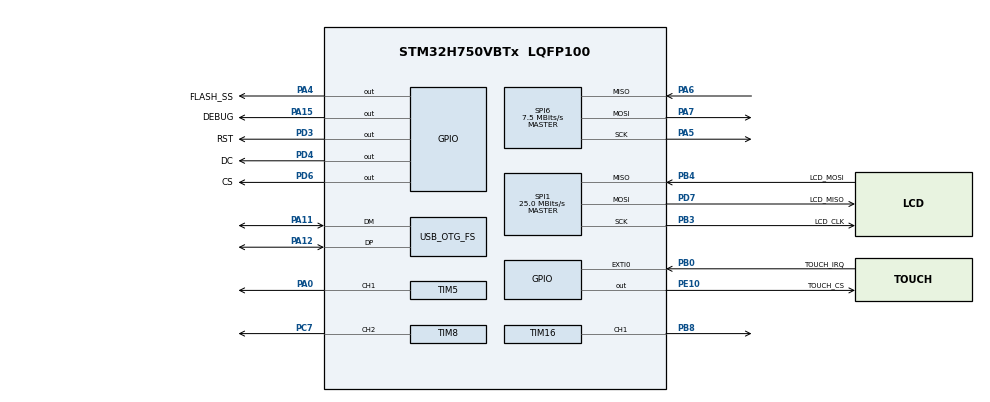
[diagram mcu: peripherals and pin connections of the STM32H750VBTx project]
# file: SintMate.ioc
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CORTEX_M7.CPU_DCache=Disabled
CORTEX_M7.CPU_ICache=Enabled
Dma.Request0=SPI1_TX
Dma.Request1=TIM8_CH2
Dma.SPI1_TX.0.Direction=DMA_MEMORY_TO_PERIPH
Dma.SPI1_TX.0.EventEnable=DISABLE
Dma.SPI1_TX.0.FIFOMode=DMA_FIFOMODE_DISABLE
Dma.SPI1_TX.0.Instance=DMA1_Stream0
Dma.SPI1_TX.0.MemDataAlignment=DMA_MDATAALIGN_BYTE
Dma.SPI1_TX.0.MemInc=DMA_MINC_ENABLE
Dma.SPI1_TX.0.Mode=DMA_NORMAL
Dma.SPI1_TX.0.PeriphDataAlignment=DMA_PDATAALIGN_BYTE
Dma.SPI1_TX.0.PeriphInc=DMA_PINC_DISABLE
Dma.SPI1_TX.0.Polarity=HAL_DMAMUX_REQ_GEN_RISING
Dma.SPI1_TX.0.Priority=DMA_PRIORITY_LOW
Dma.SPI1_TX.0.RequestNumber=1
Dma.SPI1_TX.0.SignalID=NONE
Dma.SPI1_TX.0.SyncEnable=DISABLE
Dma.SPI1_TX.0.SyncPolarity=HAL_DMAMUX_SYNC_NO_EVENT
Dma.SPI1_TX.0.SyncRequestNumber=1
Dma.SPI1_TX.0.SyncSignalID=NONE
Dma.TIM8_CH2.1.Direction=DMA_MEMORY_TO_PERIPH
Dma.TIM8_CH2.1.EventEnable=DISABLE
Dma.TIM8_CH2.1.FIFOMode=DMA_FIFOMODE_DISABLE
Dma.TIM8_CH2.1.Instance=DMA1_Stream1
Dma.TIM8_CH2.1.MemDataAlignment=DMA_MDATAALIGN_WORD
Dma.TIM8_CH2.1.MemInc=DMA_MINC_ENABLE
Dma.TIM8_CH2.1.Mode=DMA_CIRCULAR
Dma.TIM8_CH2.1.PeriphDataAlignment=DMA_PDATAALIGN_WORD
Dma.TIM8_CH2.1.PeriphInc=DMA_PINC_DISABLE
Dma.TIM8_CH2.1.Polarity=HAL_DMAMUX_REQ_GEN_RISING
Dma.TIM8_CH2.1.Priority=DMA_PRIORITY_LOW
Dma.TIM8_CH2.1.RequestNumber=1
Dma.TIM8_CH2.1.SignalID=NONE
Dma.TIM8_CH2.1.SyncEnable=DISABLE
Dma.TIM8_CH2.1.SyncPolarity=HAL_DMAMUX_SYNC_NO_EVENT
Dma.TIM8_CH2.1.SyncRequestNumber=1
Dma.TIM8_CH2.1.SyncSignalID=NONE
Mcu.Family=STM32H7
Mcu.Name=STM32H750VBTx
Mcu.Package=LQFP100
NVIC.DMA1_Stream0_IRQn=true\:0\:0\:false\:false\:true\:false\:true
NVIC.DMA1_Stream1_IRQn=true\:0\:0\:false\:false\:true\:false\:true
NVIC.EXTI0_IRQn=true\:0\:0\:false\:false\:true\:true\:true
NVIC.OTG_FS_IRQn=true\:0\:0\:false\:false\:true\:false\:true
NVIC.PriorityGroup=NVIC_PRIORITYGROUP_4
NVIC.SPI1_IRQn=true\:0\:0\:false\:false\:true\:false\:true
NVIC.TIM7_IRQn=true\:0\:0\:false\:false\:true\:true\:true
PA0.Signal=S_TIM5_CH1
PA11.Mode=Device_Only
PA11.Signal=USB_OTG_FS_DM
PA12.Mode=Device_Only
PA12.Signal=USB_OTG_FS_DP
PA15\ (JTDI).GPIO_Label=DEBUG
PA15\ (JTDI).Signal=GPIO_Output
PA4.GPIO_Label=FLASH_SS
PA4.Signal=GPIO_Output
PA5.Mode=Full_Duplex_Master
PA5.Signal=SPI6_SCK
PA6.Mode=Full_Duplex_Master
PA6.Signal=SPI6_MISO
PA7.Mode=Full_Duplex_Master
PA7.Signal=SPI6_MOSI
PB0.GPIO_Label=TOUCH_IRQ
PB0.GPIO_ModeDefaultEXTI=GPIO_MODE_IT_RISING_FALLING
PB0.GPIO_PuPd=GPIO_PULLUP
PB0.Signal=GPXTI0
PB3\ (JTDO/TRACESWO).GPIO_Label=LCD_CLK
PB3\ (JTDO/TRACESWO).Mode=Full_Duplex_Master
PB3\ (JTDO/TRACESWO).Signal=SPI1_SCK
PB4\ (NJTRST).GPIO_Label=LCD_MOSI
PB4\ (NJTRST).Mode=Full_Duplex_Master
PB4\ (NJTRST).Signal=SPI1_MISO
PB8.Signal=S_TIM16_CH1
PC7.Signal=S_TIM8_CH2
PD3.GPIO_Label=RST
PD3.Signal=GPIO_Output
PD4.GPIO_Label=DC
PD4.GPIO_Speed=GPIO_SPEED_FREQ_HIGH
PD4.Signal=GPIO_Output
PD6.GPIO_Label=CS
PD6.GPIO_Speed=GPIO_SPEED_FREQ_HIGH
PD6.PinState=GPIO_PIN_SET
PD6.Signal=GPIO_Output
PD7.GPIO_Label=LCD_MISO
PD7.Mode=Full_Duplex_Master
PD7.Signal=SPI1_MOSI
PE10.GPIO_Label=TOUCH_CS
PE10.GPIO_Speed=GPIO_SPEED_FREQ_HIGH
PE10.PinState=GPIO_PIN_SET
PE10.Signal=GPIO_Output
PH0-OSC_IN\ (PH0).Mode=HSE-External-Oscillator
PH0-OSC_IN\ (PH0).Signal=RCC_OSC_IN
PH1-OSC_OUT\ (PH1).Mode=HSE-External-Oscillator
PH1-OSC_OUT\ (PH1).Signal=RCC_OSC_OUT
ProjectManager.HeapSize=0x200
ProjectManager.StackSize=0x400
ProjectManager.TargetToolchain=STM32CubeIDE
RCC.ADCFreq_Value=200000000
RCC.APB1Freq_Value=120000000
RCC.APB2Freq_Value=120000000
RCC.APB3Freq_Value=120000000
RCC.APB4Freq_Value=120000000
RCC.CortexFreq_Value=480000000
RCC.D1PPRE=RCC_APB3_DIV2
RCC.D2PPRE1=RCC_APB1_DIV2
RCC.D2PPRE2=RCC_APB2_DIV2
RCC.D3PPRE=RCC_APB4_DIV2
RCC.DIVM1=2
RCC.DIVM2=12
RCC.DIVM3=16
RCC.DIVN1=80
RCC.DIVN2=200
RCC.DIVN3=144
RCC.DIVP3=1
RCC.HCLKFreq_Value=240000000
RCC.HPRE=RCC_HCLK_DIV2
RCC.HSE_VALUE=24000000
RCC.PLLFRACN=0
RCC.PLLSourceVirtual=RCC_PLLSOURCE_HSE
RCC.SPI123CLockSelection=RCC_SPI123CLKSOURCE_PLL2
RCC.SYSCLKFreq_VALUE=480000000
RCC.SYSCLKSource=RCC_SYSCLKSOURCE_PLLCLK
RCC.USBCLockSelection=RCC_USBCLKSOURCE_HSI48
RCC.USBFreq_Value=48000000
RCC.VDD_VALUE=3
SH.S_TIM16_CH1.0=TIM16_CH1,Output Compare1 CH1
SH.S_TIM5_CH1.0=TIM5_CH1,PWM Generation1 CH1
SH.S_TIM8_CH2.0=TIM8_CH2,PWM Generation2 CH2
SPI1.BaudRatePrescaler=SPI_BAUDRATEPRESCALER_8
SPI1.CalculateBaudRate=25.0 MBits/s
SPI1.DataSize=SPI_DATASIZE_8BIT
SPI1.Direction=SPI_DIRECTION_2LINES
SPI1.Mode=SPI_MODE_MASTER
SPI1.VirtualType=VM_MASTER
SPI6.BaudRatePrescaler=SPI_BAUDRATEPRESCALER_16
SPI6.CalculateBaudRate=7.5 MBits/s
SPI6.DataSize=SPI_DATASIZE_8BIT
SPI6.Direction=SPI_DIRECTION_2LINES
SPI6.Mode=SPI_MODE_MASTER
SPI6.VirtualType=VM_MASTER
TIM16.Channel=TIM_CHANNEL_1
TIM16.OCMode_1=TIM_OCMODE_TOGGLE
TIM16.Period=50
TIM16.Prescaler=8571
TIM16.Pulse=25
TIM16.RepetitionCounter=7
TIM5.Channel-PWM\ Generation1\ CH1=TIM_CHANNEL_1
TIM5.Period=1000
TIM5.Prescaler=240
TIM5.Pulse-PWM\ Generation1\ CH1=500
TIM7.Period=10000
TIM7.Prescaler=2400
TIM8.Channel-PWM\ Generation2\ CH2=TIM_CHANNEL_2
TIM8.Period=1200
TIM8.Prescaler=3
TIM8.Pulse-PWM\ Generation2\ CH2=400
USB_DEVICE.CLASS_NAME_FS=CDC
USB_DEVICE.VirtualMode-CDC_FS=Cdc
USB_DEVICE.VirtualModeFS=Cdc_FS
USB_OTG_FS.VirtualMode=Device_Only
VP_TIM16_VS_ClockSourceINT.Mode=Enable_Timer
VP_TIM16_VS_OPM.Mode=OPM_bit
VP_TIM7_VS_ClockSourceINT.Mode=Enable_Timer
VP_USB_DEVICE_VS_USB_DEVICE_CDC_FS.Mode=CDC_FS
board=custom

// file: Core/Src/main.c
/* USER CODE BEGIN Header */
/**
  ******************************************************************************
  * @file           : main.c
  * @brief          : Main program body
  ******************************************************************************
  * @attention
  *
  * <h2><center>&copy; Copyright (c) 2021 STMicroelectronics.
  * All rights reserved.</center></h2>
  *
  * This software component is licensed by ST under BSD 3-Clause license,
  * the "License"; You may not use this file except in compliance with the
  * License. You may obtain a copy of the License at:
  *                        opensource.org/licenses/BSD-3-Clause
  *
  ******************************************************************************
  */
/* USER CODE END Header */
#include "main.h"
#include "usb_device.h"

/* USER CODE BEGIN Includes */
#include <stdio.h>
#include <string.h>

/* USER CODE END Includes */

SPI_HandleTypeDef hspi1;
SPI_HandleTypeDef hspi6;
DMA_HandleTypeDef hdma_spi1_tx;

TIM_HandleTypeDef htim5;
TIM_HandleTypeDef htim7;
TIM_HandleTypeDef htim8;
TIM_HandleTypeDef htim16;
DMA_HandleTypeDef hdma_tim8_ch2;

void SystemClock_Config(void);
static void MX_GPIO_Init(void);
static void MX_DMA_Init(void);
static void MX_SPI1_Init(void);
static void MX_SPI6_Init(void);
static void MX_TIM5_Init(void);
static void MX_TIM7_Init(void);
static void MX_TIM16_Init(void);
static void MX_TIM8_Init(void);

int main(void)
{

  /* Enable I-Cache---------------------------------------------------------*/
  SCB_EnableICache();

  /* MCU Configuration--------------------------------------------------------*/

  /* Reset of all peripherals, Initializes the Flash interface and the Systick. */
  HAL_Init();

  /* Configure the system clock */
  SystemClock_Config();

  /* USER CODE BEGIN SysInit */
  __HAL_RCC_D2SRAM1_CLK_ENABLE();
  __HAL_RCC_D2SRAM2_CLK_ENABLE();
  __HAL_RCC_D2SRAM3_CLK_ENABLE();

  /* USER CODE END SysInit */

  /* Initialize all configured peripherals */
  MX_GPIO_Init();
  MX_DMA_Init();
  MX_SPI1_Init();
  MX_SPI6_Init();
  MX_TIM5_Init();
  MX_TIM7_Init();
  MX_TIM16_Init();
  MX_TIM8_Init();
  MX_USB_DEVICE_Init();
  /* USER CODE BEGIN 2 */
  Init_SintMate();
  /* USER CODE END 2 */

  /* Infinite loop */
  /* USER CODE BEGIN WHILE */
  while (1)
  {
	  SintMateLoop();

	  //DoNumberOfSteps(4);
	  /*
		HAL_TIM_OC_Start(&htim16, TIM_CHANNEL_1);
		HAL_Delay(100);
		//HAL_TIM_OC_Stop(&htim16, TIM_CHANNEL_1);
		 *
		 */

    /* USER CODE END WHILE */

  }
}

void SystemClock_Config(void)
{
  RCC_OscInitTypeDef RCC_OscInitStruct = {0};
  RCC_ClkInitTypeDef RCC_ClkInitStruct = {0};
  RCC_PeriphCLKInitTypeDef PeriphClkInitStruct = {0};

  /** Supply configuration update enable
  */
  HAL_PWREx_ConfigSupply(PWR_LDO_SUPPLY);
  /** Configure the main internal regulator output voltage
  */
  __HAL_PWR_VOLTAGESCALING_CONFIG(PWR_REGULATOR_VOLTAGE_SCALE0);

  while(!__HAL_PWR_GET_FLAG(PWR_FLAG_VOSRDY)) {}
  /** Macro to configure the PLL clock source
  */
  __HAL_RCC_PLL_PLLSOURCE_CONFIG(RCC_PLLSOURCE_HSE);
  /** Initializes the RCC Oscillators according to the specified parameters
  * in the RCC_OscInitTypeDef structure.
  */
  RCC_OscInitStruct.OscillatorType = RCC_OSCILLATORTYPE_HSI48|RCC_OSCILLATORTYPE_HSE;
  RCC_OscInitStruct.HSEState = RCC_HSE_ON;
  RCC_OscInitStruct.HSI48State = RCC_HSI48_ON;
  RCC_OscInitStruct.PLL.PLLState = RCC_PLL_ON;
  RCC_OscInitStruct.PLL.PLLSource = RCC_PLLSOURCE_HSE;
  RCC_OscInitStruct.PLL.PLLM = 2;
  RCC_OscInitStruct.PLL.PLLN = 80;
  RCC_OscInitStruct.PLL.PLLP = 2;
  RCC_OscInitStruct.PLL.PLLQ = 2;
  RCC_OscInitStruct.PLL.PLLR = 2;
  RCC_OscInitStruct.PLL.PLLRGE = RCC_PLL1VCIRANGE_3;
  RCC_OscInitStruct.PLL.PLLVCOSEL = RCC_PLL1VCOWIDE;
  RCC_OscInitStruct.PLL.PLLFRACN = 0;
  if (HAL_RCC_OscConfig(&RCC_OscInitStruct) != HAL_OK)
  {
    Error_Handler();
  }
  /** Initializes the CPU, AHB and APB buses clocks
  */
  RCC_ClkInitStruct.ClockType = RCC_CLOCKTYPE_HCLK|RCC_CLOCKTYPE_SYSCLK
                              |RCC_CLOCKTYPE_PCLK1|RCC_CLOCKTYPE_PCLK2
                              |RCC_CLOCKTYPE_D3PCLK1|RCC_CLOCKTYPE_D1PCLK1;
  RCC_ClkInitStruct.SYSCLKSource = RCC_SYSCLKSOURCE_PLLCLK;
  RCC_ClkInitStruct.SYSCLKDivider = RCC_SYSCLK_DIV1;
  RCC_ClkInitStruct.AHBCLKDivider = RCC_HCLK_DIV2;
  RCC_ClkInitStruct.APB3CLKDivider = RCC_APB3_DIV2;
  RCC_ClkInitStruct.APB1CLKDivider = RCC_APB1_DIV2;
  RCC_ClkInitStruct.APB2CLKDivider = RCC_APB2_DIV2;
  RCC_ClkInitStruct.APB4CLKDivider = RCC_APB4_DIV2;

  if (HAL_RCC_ClockConfig(&RCC_ClkInitStruct, FLASH_LATENCY_4) != HAL_OK)
  {
    Error_Handler();
  }
  PeriphClkInitStruct.PeriphClockSelection = RCC_PERIPHCLK_SPI1|RCC_PERIPHCLK_SPI6
                              |RCC_PERIPHCLK_USB;
  PeriphClkInitStruct.PLL2.PLL2M = 12;
  PeriphClkInitStruct.PLL2.PLL2N = 200;
  PeriphClkInitStruct.PLL2.PLL2P = 2;
  PeriphClkInitStruct.PLL2.PLL2Q = 2;
  PeriphClkInitStruct.PLL2.PLL2R = 2;
  PeriphClkInitStruct.PLL2.PLL2RGE = RCC_PLL2VCIRANGE_1;
  PeriphClkInitStruct.PLL2.PLL2VCOSEL = RCC_PLL2VCOWIDE;
  PeriphClkInitStruct.PLL2.PLL2FRACN = 0;
  PeriphClkInitStruct.Spi123ClockSelection = RCC_SPI123CLKSOURCE_PLL2;
  PeriphClkInitStruct.UsbClockSelection = RCC_USBCLKSOURCE_HSI48;
  PeriphClkInitStruct.Spi6ClockSelection = RCC_SPI6CLKSOURCE_D3PCLK1;
  if (HAL_RCCEx_PeriphCLKConfig(&PeriphClkInitStruct) != HAL_OK)
  {
    Error_Handler();
  }
  /** Enable USB Voltage detector
  */
  HAL_PWREx_EnableUSBVoltageDetector();
}

static void MX_SPI1_Init(void)
{

  /* SPI1 parameter configuration*/
  hspi1.Instance = SPI1;
  hspi1.Init.Mode = SPI_MODE_MASTER;
  hspi1.Init.Direction = SPI_DIRECTION_2LINES;
  hspi1.Init.DataSize = SPI_DATASIZE_8BIT;
  hspi1.Init.CLKPolarity = SPI_POLARITY_LOW;
  hspi1.Init.CLKPhase = SPI_PHASE_1EDGE;
  hspi1.Init.NSS = SPI_NSS_SOFT;
  hspi1.Init.BaudRatePrescaler = SPI_BAUDRATEPRESCALER_8;
  hspi1.Init.FirstBit = SPI_FIRSTBIT_MSB;
  hspi1.Init.TIMode = SPI_TIMODE_DISABLE;
  hspi1.Init.CRCCalculation = SPI_CRCCALCULATION_DISABLE;
  hspi1.Init.CRCPolynomial = 0x0;
  hspi1.Init.NSSPMode = SPI_NSS_PULSE_ENABLE;
  hspi1.Init.NSSPolarity = SPI_NSS_POLARITY_LOW;
  hspi1.Init.FifoThreshold = SPI_FIFO_THRESHOLD_01DATA;
  hspi1.Init.TxCRCInitializationPattern = SPI_CRC_INITIALIZATION_ALL_ZERO_PATTERN;
  hspi1.Init.RxCRCInitializationPattern = SPI_CRC_INITIALIZATION_ALL_ZERO_PATTERN;
  hspi1.Init.MasterSSIdleness = SPI_MASTER_SS_IDLENESS_00CYCLE;
  hspi1.Init.MasterInterDataIdleness = SPI_MASTER_INTERDATA_IDLENESS_00CYCLE;
  hspi1.Init.MasterReceiverAutoSusp = SPI_MASTER_RX_AUTOSUSP_DISABLE;
  hspi1.Init.MasterKeepIOState = SPI_MASTER_KEEP_IO_STATE_DISABLE;
  hspi1.Init.IOSwap = SPI_IO_SWAP_DISABLE;
  if (HAL_SPI_Init(&hspi1) != HAL_OK)
  {
    Error_Handler();
  }

}

static void MX_SPI6_Init(void)
{

  /* SPI6 parameter configuration*/
  hspi6.Instance = SPI6;
  hspi6.Init.Mode = SPI_MODE_MASTER;
  hspi6.Init.Direction = SPI_DIRECTION_2LINES;
  hspi6.Init.DataSize = SPI_DATASIZE_8BIT;
  hspi6.Init.CLKPolarity = SPI_POLARITY_LOW;
  hspi6.Init.CLKPhase = SPI_PHASE_1EDGE;
  hspi6.Init.NSS = SPI_NSS_SOFT;
  hspi6.Init.BaudRatePrescaler = SPI_BAUDRATEPRESCALER_16;
  hspi6.Init.FirstBit = SPI_FIRSTBIT_MSB;
  hspi6.Init.TIMode = SPI_TIMODE_DISABLE;
  hspi6.Init.CRCCalculation = SPI_CRCCALCULATION_DISABLE;
  hspi6.Init.CRCPolynomial = 0x0;
  hspi6.Init.NSSPMode = SPI_NSS_PULSE_ENABLE;
  hspi6.Init.NSSPolarity = SPI_NSS_POLARITY_LOW;
  hspi6.Init.FifoThreshold = SPI_FIFO_THRESHOLD_01DATA;
  hspi6.Init.TxCRCInitializationPattern = SPI_CRC_INITIALIZATION_ALL_ZERO_PATTERN;
  hspi6.Init.RxCRCInitializationPattern = SPI_CRC_INITIALIZATION_ALL_ZERO_PATTERN;
  hspi6.Init.MasterSSIdleness = SPI_MASTER_SS_IDLENESS_00CYCLE;
  hspi6.Init.MasterInterDataIdleness = SPI_MASTER_INTERDATA_IDLENESS_00CYCLE;
  hspi6.Init.MasterReceiverAutoSusp = SPI_MASTER_RX_AUTOSUSP_DISABLE;
  hspi6.Init.MasterKeepIOState = SPI_MASTER_KEEP_IO_STATE_DISABLE;
  hspi6.Init.IOSwap = SPI_IO_SWAP_DISABLE;
  if (HAL_SPI_Init(&hspi6) != HAL_OK)
  {
    Error_Handler();
  }

}

static void MX_TIM5_Init(void)
{

  TIM_MasterConfigTypeDef sMasterConfig = {0};
  TIM_OC_InitTypeDef sConfigOC = {0};

  htim5.Instance = TIM5;
  htim5.Init.Prescaler = 240;
  htim5.Init.CounterMode = TIM_COUNTERMODE_UP;
  htim5.Init.Period = 1000;
  htim5.Init.ClockDivision = TIM_CLOCKDIVISION_DIV1;
  htim5.Init.AutoReloadPreload = TIM_AUTORELOAD_PRELOAD_DISABLE;
  if (HAL_TIM_PWM_Init(&htim5) != HAL_OK)
  {
    Error_Handler();
  }
  sMasterConfig.MasterOutputTrigger = TIM_TRGO_RESET;
  sMasterConfig.MasterSlaveMode = TIM_MASTERSLAVEMODE_DISABLE;
  if (HAL_TIMEx_MasterConfigSynchronization(&htim5, &sMasterConfig) != HAL_OK)
  {
    Error_Handler();
  }
  sConfigOC.OCMode = TIM_OCMODE_PWM1;
  sConfigOC.Pulse = 500;
  sConfigOC.OCPolarity = TIM_OCPOLARITY_HIGH;
  sConfigOC.OCFastMode = TIM_OCFAST_DISABLE;
  if (HAL_TIM_PWM_ConfigChannel(&htim5, &sConfigOC, TIM_CHANNEL_1) != HAL_OK)
  {
    Error_Handler();
  }
  HAL_TIM_MspPostInit(&htim5);

}

static void MX_TIM7_Init(void)
{

  TIM_MasterConfigTypeDef sMasterConfig = {0};

  htim7.Instance = TIM7;
  htim7.Init.Prescaler = 2400;
  htim7.Init.CounterMode = TIM_COUNTERMODE_UP;
  htim7.Init.Period = 10000;
  htim7.Init.AutoReloadPreload = TIM_AUTORELOAD_PRELOAD_DISABLE;
  if (HAL_TIM_Base_Init(&htim7) != HAL_OK)
  {
    Error_Handler();
  }
  sMasterConfig.MasterOutputTrigger = TIM_TRGO_RESET;
  sMasterConfig.MasterSlaveMode = TIM_MASTERSLAVEMODE_DISABLE;
  if (HAL_TIMEx_MasterConfigSynchronization(&htim7, &sMasterConfig) != HAL_OK)
  {
    Error_Handler();
  }

}

static void MX_TIM8_Init(void)
{

  TIM_MasterConfigTypeDef sMasterConfig = {0};
  TIM_OC_InitTypeDef sConfigOC = {0};
  TIM_BreakDeadTimeConfigTypeDef sBreakDeadTimeConfig = {0};

  htim8.Instance = TIM8;
  htim8.Init.Prescaler = 3;
  htim8.Init.CounterMode = TIM_COUNTERMODE_UP;
  htim8.Init.Period = 1200;
  htim8.Init.ClockDivision = TIM_CLOCKDIVISION_DIV1;
  htim8.Init.RepetitionCounter = 0;
  htim8.Init.AutoReloadPreload = TIM_AUTORELOAD_PRELOAD_DISABLE;
  if (HAL_TIM_PWM_Init(&htim8) != HAL_OK)
  {
    Error_Handler();
  }
  sMasterConfig.MasterOutputTrigger = TIM_TRGO_RESET;
  sMasterConfig.MasterOutputTrigger2 = TIM_TRGO2_RESET;
  sMasterConfig.MasterSlaveMode = TIM_MASTERSLAVEMODE_DISABLE;
  if (HAL_TIMEx_MasterConfigSynchronization(&htim8, &sMasterConfig) != HAL_OK)
  {
    Error_Handler();
  }
  sConfigOC.OCMode = TIM_OCMODE_PWM1;
  sConfigOC.Pulse = 400;
  sConfigOC.OCPolarity = TIM_OCPOLARITY_HIGH;
  sConfigOC.OCNPolarity = TIM_OCNPOLARITY_HIGH;
  sConfigOC.OCFastMode = TIM_OCFAST_DISABLE;
  sConfigOC.OCIdleState = TIM_OCIDLESTATE_RESET;
  sConfigOC.OCNIdleState = TIM_OCNIDLESTATE_RESET;
  if (HAL_TIM_PWM_ConfigChannel(&htim8, &sConfigOC, TIM_CHANNEL_2) != HAL_OK)
  {
    Error_Handler();
  }
  sBreakDeadTimeConfig.OffStateRunMode = TIM_OSSR_DISABLE;
  sBreakDeadTimeConfig.OffStateIDLEMode = TIM_OSSI_DISABLE;
  sBreakDeadTimeConfig.LockLevel = TIM_LOCKLEVEL_OFF;
  sBreakDeadTimeConfig.DeadTime = 0;
  sBreakDeadTimeConfig.BreakState = TIM_BREAK_DISABLE;
  sBreakDeadTimeConfig.BreakPolarity = TIM_BREAKPOLARITY_HIGH;
  sBreakDeadTimeConfig.BreakFilter = 0;
  sBreakDeadTimeConfig.Break2State = TIM_BREAK2_DISABLE;
  sBreakDeadTimeConfig.Break2Polarity = TIM_BREAK2POLARITY_HIGH;
  sBreakDeadTimeConfig.Break2Filter = 0;
  sBreakDeadTimeConfig.AutomaticOutput = TIM_AUTOMATICOUTPUT_DISABLE;
  if (HAL_TIMEx_ConfigBreakDeadTime(&htim8, &sBreakDeadTimeConfig) != HAL_OK)
  {
    Error_Handler();
  }
  HAL_TIM_MspPostInit(&htim8);

}

static void MX_TIM16_Init(void)
{

  TIM_OC_InitTypeDef sConfigOC = {0};
  TIM_BreakDeadTimeConfigTypeDef sBreakDeadTimeConfig = {0};

  htim16.Instance = TIM16;
  htim16.Init.Prescaler = 8571;
  htim16.Init.CounterMode = TIM_COUNTERMODE_UP;
  htim16.Init.Period = 50;
  htim16.Init.ClockDivision = TIM_CLOCKDIVISION_DIV1;
  htim16.Init.RepetitionCounter = 7;
  htim16.Init.AutoReloadPreload = TIM_AUTORELOAD_PRELOAD_DISABLE;
  if (HAL_TIM_Base_Init(&htim16) != HAL_OK)
  {
    Error_Handler();
  }
  if (HAL_TIM_OC_Init(&htim16) != HAL_OK)
  {
    Error_Handler();
  }
  if (HAL_TIM_OnePulse_Init(&htim16, TIM_OPMODE_SINGLE) != HAL_OK)
  {
    Error_Handler();
  }
  sConfigOC.OCMode = TIM_OCMODE_TOGGLE;
  sConfigOC.Pulse = 25;
  sConfigOC.OCPolarity = TIM_OCPOLARITY_HIGH;
  sConfigOC.OCNPolarity = TIM_OCNPOLARITY_HIGH;
  sConfigOC.OCFastMode = TIM_OCFAST_DISABLE;
  sConfigOC.OCIdleState = TIM_OCIDLESTATE_RESET;
  sConfigOC.OCNIdleState = TIM_OCNIDLESTATE_RESET;
  if (HAL_TIM_OC_ConfigChannel(&htim16, &sConfigOC, TIM_CHANNEL_1) != HAL_OK)
  {
    Error_Handler();
  }
  sBreakDeadTimeConfig.OffStateRunMode = TIM_OSSR_DISABLE;
  sBreakDeadTimeConfig.OffStateIDLEMode = TIM_OSSI_DISABLE;
  sBreakDeadTimeConfig.LockLevel = TIM_LOCKLEVEL_OFF;
  sBreakDeadTimeConfig.DeadTime = 0;
  sBreakDeadTimeConfig.BreakState = TIM_BREAK_DISABLE;
  sBreakDeadTimeConfig.BreakPolarity = TIM_BREAKPOLARITY_HIGH;
  sBreakDeadTimeConfig.BreakFilter = 0;
  sBreakDeadTimeConfig.AutomaticOutput = TIM_AUTOMATICOUTPUT_DISABLE;
  if (HAL_TIMEx_ConfigBreakDeadTime(&htim16, &sBreakDeadTimeConfig) != HAL_OK)
  {
    Error_Handler();
  }
  HAL_TIM_MspPostInit(&htim16);

}

static void MX_DMA_Init(void)
{

  /* DMA controller clock enable */
  __HAL_RCC_DMA1_CLK_ENABLE();

  /* DMA interrupt init */
  /* DMA1_Stream0_IRQn interrupt configuration */
  HAL_NVIC_SetPriority(DMA1_Stream0_IRQn, 0, 0);
  HAL_NVIC_EnableIRQ(DMA1_Stream0_IRQn);
  /* DMA1_Stream1_IRQn interrupt configuration */
  HAL_NVIC_SetPriority(DMA1_Stream1_IRQn, 0, 0);
  HAL_NVIC_EnableIRQ(DMA1_Stream1_IRQn);

}

static void MX_GPIO_Init(void)
{
  GPIO_InitTypeDef GPIO_InitStruct = {0};

  /* GPIO Ports Clock Enable */
  __HAL_RCC_GPIOH_CLK_ENABLE();
  __HAL_RCC_GPIOA_CLK_ENABLE();
  __HAL_RCC_GPIOB_CLK_ENABLE();
  __HAL_RCC_GPIOE_CLK_ENABLE();
  __HAL_RCC_GPIOC_CLK_ENABLE();
  __HAL_RCC_GPIOD_CLK_ENABLE();

  /*Configure GPIO pin Output Level */
  HAL_GPIO_WritePin(GPIOA, FLASH_SS_Pin|DEBUG_Pin, GPIO_PIN_RESET);

  /*Configure GPIO pin Output Level */
  HAL_GPIO_WritePin(TOUCH_CS_GPIO_Port, TOUCH_CS_Pin, GPIO_PIN_SET);

  /*Configure GPIO pin Output Level */
  HAL_GPIO_WritePin(GPIOD, RST_Pin|DC_Pin, GPIO_PIN_RESET);

  /*Configure GPIO pin Output Level */
  HAL_GPIO_WritePin(CS_GPIO_Port, CS_Pin, GPIO_PIN_SET);

  /*Configure GPIO pins : FLASH_SS_Pin DEBUG_Pin */
  GPIO_InitStruct.Pin = FLASH_SS_Pin|DEBUG_Pin;
  GPIO_InitStruct.Mode = GPIO_MODE_OUTPUT_PP;
  GPIO_InitStruct.Pull = GPIO_NOPULL;
  GPIO_InitStruct.Speed = GPIO_SPEED_FREQ_LOW;
  HAL_GPIO_Init(GPIOA, &GPIO_InitStruct);

  /*Configure GPIO pin : TOUCH_IRQ_Pin */
  GPIO_InitStruct.Pin = TOUCH_IRQ_Pin;
  GPIO_InitStruct.Mode = GPIO_MODE_IT_RISING_FALLING;
  GPIO_InitStruct.Pull = GPIO_PULLUP;
  HAL_GPIO_Init(TOUCH_IRQ_GPIO_Port, &GPIO_InitStruct);

  /*Configure GPIO pin : TOUCH_CS_Pin */
  GPIO_InitStruct.Pin = TOUCH_CS_Pin;
  GPIO_InitStruct.Mode = GPIO_MODE_OUTPUT_PP;
  GPIO_InitStruct.Pull = GPIO_NOPULL;
  GPIO_InitStruct.Speed = GPIO_SPEED_FREQ_HIGH;
  HAL_GPIO_Init(TOUCH_CS_GPIO_Port, &GPIO_InitStruct);

  /*Configure GPIO pin : RST_Pin */
  GPIO_InitStruct.Pin = RST_Pin;
  GPIO_InitStruct.Mode = GPIO_MODE_OUTPUT_PP;
  GPIO_InitStruct.Pull = GPIO_NOPULL;
  GPIO_InitStruct.Speed = GPIO_SPEED_FREQ_LOW;
  HAL_GPIO_Init(RST_GPIO_Port, &GPIO_InitStruct);

  /*Configure GPIO pins : DC_Pin CS_Pin */
  GPIO_InitStruct.Pin = DC_Pin|CS_Pin;
  GPIO_InitStruct.Mode = GPIO_MODE_OUTPUT_PP;
  GPIO_InitStruct.Pull = GPIO_NOPULL;
  GPIO_InitStruct.Speed = GPIO_SPEED_FREQ_HIGH;
  HAL_GPIO_Init(GPIOD, &GPIO_InitStruct);

  /* EXTI interrupt init*/
  HAL_NVIC_SetPriority(EXTI0_IRQn, 0, 0);
  HAL_NVIC_EnableIRQ(EXTI0_IRQn);

}

void Error_Handler(void)
{
  __disable_irq();
  while (1)
  {
  }
}

/************************ (C) COPYRIGHT STMicroelectronics *****END OF FILE****/
